# nrf54h20_engb_application register map
Vendor: Nordic Semiconductor; Series: nRF54h; File version: 1
CPU: CM33 r0p4, little endian, MPU, FPU, 3 interrupt priority bits, 480 interrupts, 8 SAU regions
Registers are 32-bit, read-write, reset 0x0 unless marked. A register's access mark holds for its fields unless they carry their own. Offsets are from the block's base; [hi:lo] are bit positions; lines under a group give offsets from that group; 'fields as' and 'values as' point back to an identical list.

## GLOBAL_PDM_NS — Pulse Density Modulation (Digital Microphone) Interface 0
Base 0x4F993000
Same registers: GLOBAL_PDM_S 0x5F993000
0x00 TASKS_START wo — Starts continuous PDM transfer
  [0] TASKS_START
    1=Trigger task
0x04 TASKS_STOP wo — Stops PDM transfer
  [0] TASKS_STOP
    1=Trigger task
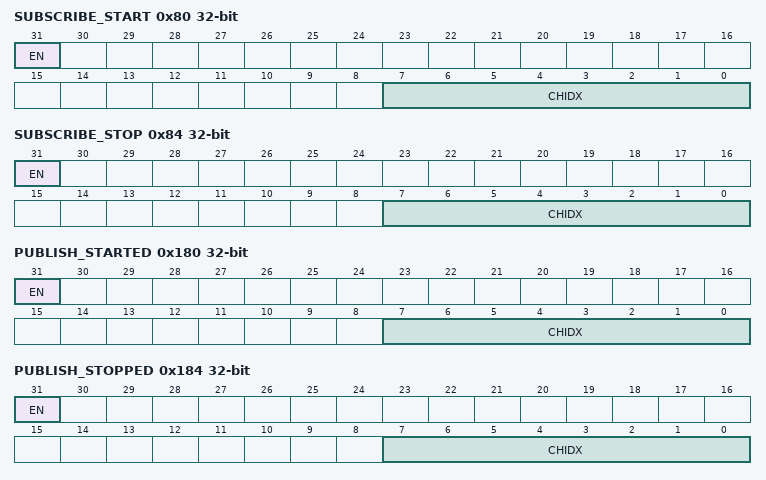
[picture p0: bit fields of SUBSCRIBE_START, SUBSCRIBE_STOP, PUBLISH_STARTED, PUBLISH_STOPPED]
0x80 SUBSCRIBE_START — Subscribe configuration for task START
  [31] EN
    0=Disabled (Disable subscription); 1=Enabled (Enable subscription)
  [7:0] CHIDX — DPPI channel that task START will subscribe to
0x84 SUBSCRIBE_STOP — Subscribe configuration for task STOP
  [31] EN
    values as SUBSCRIBE_START.EN
  [7:0] CHIDX — DPPI channel that task STOP will subscribe to
0x100 EVENTS_STARTED — PDM transfer has started
  [0] EVENTS_STARTED
    0=NotGenerated (Event not generated); 1=Generated (Event generated)
0x104 EVENTS_STOPPED — PDM transfer has finished
  [0] EVENTS_STOPPED
    values as EVENTS_STARTED.EVENTS_STARTED
0x108 EVENTS_END — The PDM has written the last sample specified by SAMPLE.MAXCNT (or the last sample after a STOP task has been received) to Data RAM
  [0] EVENTS_END
    values as EVENTS_STARTED.EVENTS_STARTED
0x110 EVENTS_DMA group — Peripheral events.
  0x00 BUSERROR — This event is generated if an error occurs during the bus transfer.
    [0] BUSERROR
      values as EVENTS_STARTED.EVENTS_STARTED
0x180 PUBLISH_STARTED — Publish configuration for event STARTED
  [31] EN
    0=Disabled (Disable publishing); 1=Enabled (Enable publishing)
  [7:0] CHIDX — DPPI channel that event STARTED will publish to
0x184 PUBLISH_STOPPED — Publish configuration for event STOPPED
  [31] EN
    values as PUBLISH_STARTED.EN
  [7:0] CHIDX — DPPI channel that event STOPPED will publish to
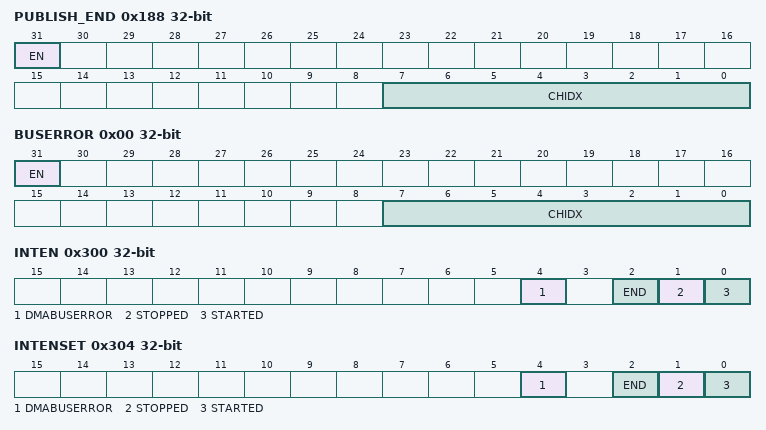
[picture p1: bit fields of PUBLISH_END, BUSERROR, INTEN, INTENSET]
0x188 PUBLISH_END — Publish configuration for event END
  [31] EN
    values as PUBLISH_STARTED.EN
  [7:0] CHIDX — DPPI channel that event END will publish to
0x190 PUBLISH_DMA group — Publish configuration for events
  0x00 BUSERROR — Publish configuration for event DMA.BUSERROR
    [31] EN
      values as PUBLISH_STARTED.EN
    [7:0] CHIDX — DPPI channel that event DMA.BUSERROR will publish to
0x200 SHORTS — Shortcuts between local events and tasks
0x300 INTEN — Enable or disable interrupt
  [all] fields
    0=Disabled; 1=Enabled
  [4] DMABUSERROR — Enable or disable interrupt for event DMABUSERROR
  [2] END — Enable or disable interrupt for event END
  [1] STOPPED — Enable or disable interrupt for event STOPPED
  [0] STARTED — Enable or disable interrupt for event STARTED
0x304 INTENSET — Enable interrupt
  [all] fields
    on read: 0=Disabled (Read: Disabled); 1=Enabled (Read: Enabled) | on write: 1=Set (Enable)
  [4] DMABUSERROR — Write '1' to enable interrupt for event DMABUSERROR
  [2] END — Write '1' to enable interrupt for event END
  [1] STOPPED — Write '1' to enable interrupt for event STOPPED
  [0] STARTED — Write '1' to enable interrupt for event STARTED
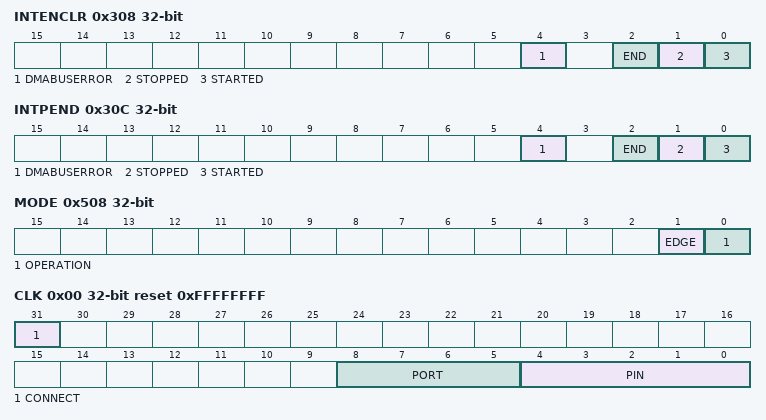
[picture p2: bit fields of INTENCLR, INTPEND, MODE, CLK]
0x308 INTENCLR — Disable interrupt
  [all] fields
    on read: 0=Disabled (Read: Disabled); 1=Enabled (Read: Enabled) | on write: 1=Clear (Disable)
  [4] DMABUSERROR — Write '1' to disable interrupt for event DMABUSERROR
  [2] END — Write '1' to disable interrupt for event END
  [1] STOPPED — Write '1' to disable interrupt for event STOPPED
  [0] STARTED — Write '1' to disable interrupt for event STARTED
0x30C INTPEND ro — Pending interrupts
  [all] fields
    on read: 0=NotPending (Read: Not pending); 1=Pending (Read: Pending)
  [4] DMABUSERROR — Read pending status of interrupt for event DMABUSERROR
  [2] END — Read pending status of interrupt for event END
  [1] STOPPED — Read pending status of interrupt for event STOPPED
  [0] STARTED — Read pending status of interrupt for event STARTED
0x500 ENABLE — PDM module enable register
  [0] ENABLE — Enable or disable PDM module
    0=Disabled; 1=Enabled
0x504 PDMCLKCTRL reset 0x8400000 — PDM clock generator control
  [31:0] FREQ — PDM_CLK frequency configuration. Enumerations are deprecated, use PDMCLKCTRL equation to find the register value. The 12 least significant bits of the register are ignored and shall be set to zero.
    0x8000000=1000K (PDM_CLK = 32 MHz / 32 = 1.000 MHz); 0x8400000=Default (PDM_CLK = 32 MHz / 31 = 1.032 MHz. Nominal clock for RATIO=Ratio64.); 0x8800000=1067K (PDM_CLK = 32 MHz / 30 = 1.067 MHz); 0x9800000=1231K (PDM_CLK = 32 MHz / 26 = 1.231 MHz); 0xA000000=1280K (PDM_CLK = 32 MHz / 25 = 1.280 MHz. Nominal clock for RATIO=Ratio80.); 0xA800000=1333K (PDM_CLK = 32 MHz / 24 = 1.333 MHz)
0x508 MODE — Defines the routing of the connected PDM microphones' signals
  [1] EDGE — Defines on which PDM_CLK edge left (or mono) is sampled.
    0=LeftFalling (Left (or mono) is sampled on falling edge of PDM_CLK); 1=LeftRising (Left (or mono) is sampled on rising edge of PDM_CLK)
  [0] OPERATION — Mono or stereo operation
    0=Stereo (Sample and store one pair (left + right) of 16-bit samples per RAM word R=[31:16]; L=[15:0]); 1=Mono (Sample and store two successive left samples (16 bits each) per RAM word L1=[31:16]; L0=[15:0])
0x518 GAINL reset 0x28 — Left output gain adjustment
  [6:0] GAINL — Left output gain adjustment, in 0.5 dB steps, around the default module gain (see electrical parameters) 0x00 -20 dB gain adjust 0x01 -19.5 dB gain adjust (...) 0x27 -0.5 dB gain adjust 0x28 0 dB gain adjust 0x29 +0.5 dB gain adjust (...) 0x4F +19.5 dB gain adjust 0x50 +20 dB gain adjust
    0=MinGain (-20 dB gain adjustment (minimum)); 40=DefaultGain (0 dB gain adjustment); 80=MaxGain (+20 dB gain adjustment (maximum))
0x51C GAINR reset 0x28 — Right output gain adjustment
  [6:0] GAINR — Right output gain adjustment, in 0.5 dB steps, around the default module gain (see electrical parameters)
    values as GAINL.GAINL
0x520 RATIO reset 0x2 — Selects the decimation ratio between PDM_CLK and output sample rate. Change PDMCLKCTRL accordingly.
  [2:0] RATIO — Selects the decimation ratio between PDM_CLK and output sample rate
    0=Ratio of 32; 1=Ratio of 48; 2=Ratio of 50; 3=Ratio of 64; 4=Ratio of 80; 5=Ratio of 96; 6=Ratio of 100; 7=Ratio of 128
0x540 PSEL group — Unspecified
  0x00 CLK reset 0xFFFFFFFF — Pin number configuration for PDM CLK signal
    [31] CONNECT — Connection
      1=Disconnected; 0=Connected
    [8:5] PORT — Port number
    [4:0] PIN — Pin number
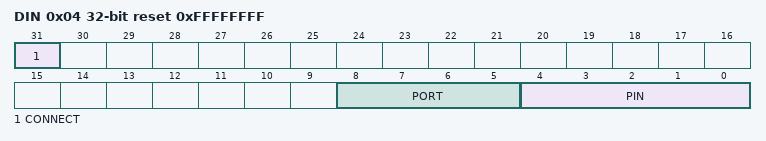
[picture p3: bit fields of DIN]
  0x04 DIN reset 0xFFFFFFFF — Pin number configuration for PDM DIN signal
    fields as PSEL.CLK
0x54C MCLKCONFIG — Master clock generator configuration
  [0] SRC — Master clock source selection
    0=PCLK32M (32 MHz peripheral clock); 1=ACLK (Audio PLL clock)
0x560 SAMPLE group — Unspecified
  0x00 PTR — RAM address pointer to write samples to with EasyDMA
    [31:0] SAMPLEPTR — Address to write PDM samples to over DMA
  0x04 MAXCNT — Number of samples to allocate memory for in EasyDMA mode
    [14:0] BUFFSIZE — Length of DMA RAM allocation in number of samples
0x700 DMA group — Unspecified
  0x00 TERMINATEONBUSERROR — Terminate the transaction if a BUSERROR event is detected.
    [0] ENABLE
      0=Disabled; 1=Enabled
  0x04 BUSERRORADDRESS — Address of transaction that generated the last BUSERROR event.
    [31:0] ADDRESS
